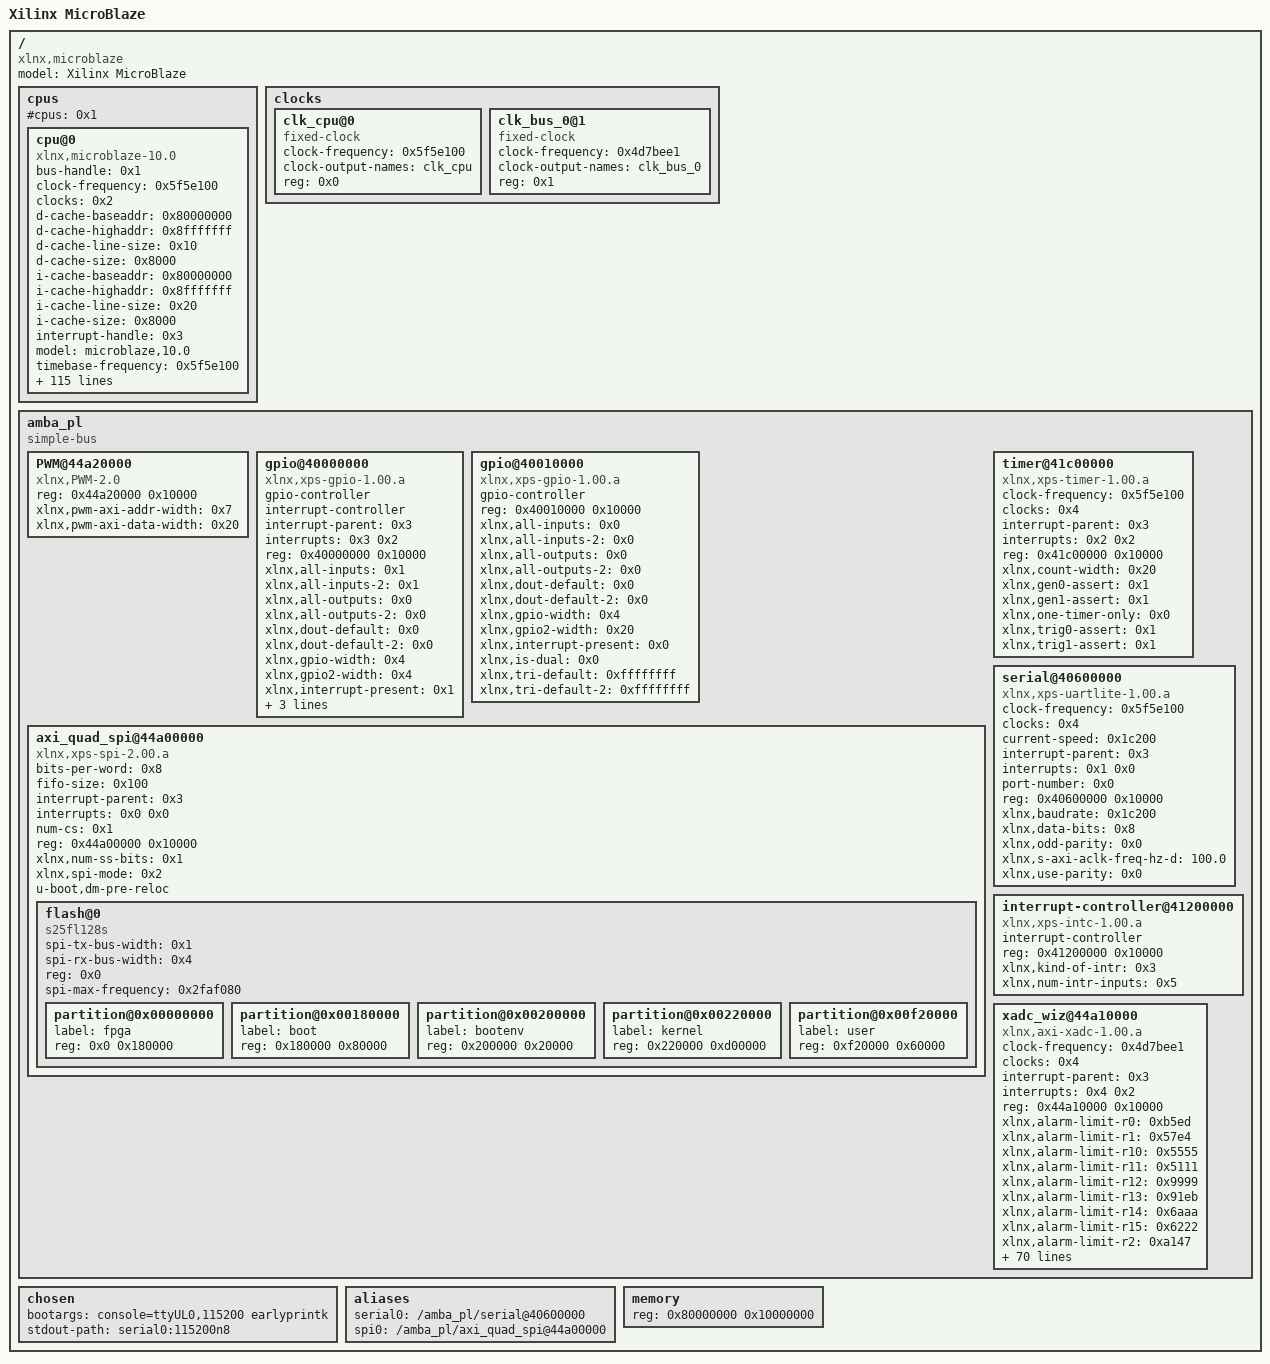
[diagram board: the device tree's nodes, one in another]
/dts-v1/;

/ {
	#address-cells = <0x1>;
	#size-cells = <0x1>;
	compatible = "xlnx,microblaze";
	model = "Xilinx MicroBlaze";

	cpus {
		#address-cells = <0x1>;
		#cpus = <0x1>;
		#size-cells = <0x0>;

		cpu@0 {
			bus-handle = <0x1>;
			clock-frequency = <0x5f5e100>;
			clocks = <0x2>;
			compatible = "xlnx,microblaze-10.0";
			d-cache-baseaddr = <0x80000000>;
			d-cache-highaddr = <0x8fffffff>;
			d-cache-line-size = <0x10>;
			d-cache-size = <0x8000>;
			device_type = "cpu";
			i-cache-baseaddr = <0x80000000>;
			i-cache-highaddr = <0x8fffffff>;
			i-cache-line-size = <0x20>;
			i-cache-size = <0x8000>;
			interrupt-handle = <0x3>;
			model = "microblaze,10.0";
			timebase-frequency = <0x5f5e100>;
			xlnx,addr-size = <0x20>;
			xlnx,addr-tag-bits = <0xd>;
			xlnx,allow-dcache-wr = <0x1>;
			xlnx,allow-icache-wr = <0x1>;
			xlnx,area-optimized = <0x0>;
			xlnx,async-interrupt = <0x1>;
			xlnx,async-wakeup = <0x3>;
			xlnx,avoid-primitives = <0x0>;
			xlnx,base-vectors = <0x0>;
			xlnx,branch-target-cache-size = <0x0>;
			xlnx,cache-byte-size = <0x8000>;
			xlnx,d-axi = <0x1>;
			xlnx,d-lmb = <0x1>;
			xlnx,d-lmb-mon = <0x0>;
			xlnx,daddr-size = <0x20>;
			xlnx,data-size = <0x20>;
			xlnx,dc-axi-mon = <0x0>;
			xlnx,dcache-addr-tag = <0xd>;
			xlnx,dcache-always-used = <0x1>;
			xlnx,dcache-byte-size = <0x8000>;
			xlnx,dcache-data-width = <0x1>;
			xlnx,dcache-force-tag-lutram = <0x0>;
			xlnx,dcache-line-len = <0x4>;
			xlnx,dcache-use-writeback = <0x1>;
			xlnx,dcache-victims = <0x0>;
			xlnx,debug-counter-width = <0x20>;
			xlnx,debug-enabled = <0x1>;
			xlnx,debug-event-counters = <0x5>;
			xlnx,debug-external-trace = <0x0>;
			xlnx,debug-interface = <0x0>;
			xlnx,debug-latency-counters = <0x1>;
			xlnx,debug-profile-size = <0x0>;
			xlnx,debug-trace-async-reset = <0x0>;
			xlnx,debug-trace-size = <0x2000>;
			xlnx,div-zero-exception = <0x1>;
			xlnx,dp-axi-mon = <0x0>;
			xlnx,dynamic-bus-sizing = <0x0>;
			xlnx,ecc-use-ce-exception = <0x0>;
			xlnx,edge-is-positive = <0x1>;
			xlnx,enable-discrete-ports = <0x0>;
			xlnx,endianness = <0x1>;
			xlnx,fault-tolerant = <0x0>;
			xlnx,fpu-exception = <0x1>;
			xlnx,freq = <0x5f5e100>;
			xlnx,fsl-exception = <0x0>;
			xlnx,fsl-links = <0x0>;
			xlnx,i-axi = <0x0>;
			xlnx,i-lmb = <0x1>;
			xlnx,i-lmb-mon = <0x0>;
			xlnx,iaddr-size = <0x20>;
			xlnx,ic-axi-mon = <0x0>;
			xlnx,icache-always-used = <0x1>;
			xlnx,icache-data-width = <0x1>;
			xlnx,icache-force-tag-lutram = <0x0>;
			xlnx,icache-line-len = <0x8>;
			xlnx,icache-streams = <0x1>;
			xlnx,icache-victims = <0x8>;
			xlnx,ill-opcode-exception = <0x1>;
			xlnx,imprecise-exceptions = <0x0>;
			xlnx,instr-size = <0x20>;
			xlnx,interconnect = <0x2>;
			xlnx,interrupt-is-edge = <0x0>;
			xlnx,interrupt-mon = <0x0>;
			xlnx,ip-axi-mon = <0x0>;
			xlnx,lockstep-master = <0x0>;
			xlnx,lockstep-select = <0x0>;
			xlnx,lockstep-slave = <0x0>;
			xlnx,mmu-dtlb-size = <0x4>;
			xlnx,mmu-itlb-size = <0x2>;
			xlnx,mmu-privileged-instr = <0x0>;
			xlnx,mmu-tlb-access = <0x3>;
			xlnx,mmu-zones = <0x2>;
			xlnx,num-sync-ff-clk = <0x2>;
			xlnx,num-sync-ff-clk-debug = <0x2>;
			xlnx,num-sync-ff-clk-irq = <0x1>;
			xlnx,num-sync-ff-dbg-clk = <0x1>;
			xlnx,num-sync-ff-dbg-trace-clk = <0x2>;
			xlnx,number-of-pc-brk = <0x2>;
			xlnx,number-of-rd-addr-brk = <0x1>;
			xlnx,number-of-wr-addr-brk = <0x1>;
			xlnx,opcode-0x0-illegal = <0x1>;
			xlnx,optimization = <0x0>;
			xlnx,pc-width = <0x20>;
			xlnx,piaddr-size = <0x20>;
			xlnx,pvr = <0x2>;
			xlnx,pvr-user1 = <0x0>;
			xlnx,pvr-user2 = <0x0>;
			xlnx,reset-msr = <0x0>;
			xlnx,reset-msr-bip = <0x0>;
			xlnx,reset-msr-dce = <0x0>;
			xlnx,reset-msr-ee = <0x0>;
			xlnx,reset-msr-eip = <0x0>;
			xlnx,reset-msr-ice = <0x0>;
			xlnx,reset-msr-ie = <0x0>;
			xlnx,sco = <0x0>;
			xlnx,trace = <0x0>;
			xlnx,unaligned-exceptions = <0x1>;
			xlnx,use-barrel = <0x1>;
			xlnx,use-branch-target-cache = <0x0>;
			xlnx,use-config-reset = <0x0>;
			xlnx,use-dcache = <0x1>;
			xlnx,use-div = <0x1>;
			xlnx,use-ext-brk = <0x0>;
			xlnx,use-ext-nm-brk = <0x0>;
			xlnx,use-extended-fsl-instr = <0x0>;
			xlnx,use-fpu = <0x1>;
			xlnx,use-hw-mul = <0x2>;
			xlnx,use-icache = <0x1>;
			xlnx,use-interrupt = <0x2>;
			xlnx,use-mmu = <0x3>;
			xlnx,use-msr-instr = <0x1>;
			xlnx,use-non-secure = <0x0>;
			xlnx,use-pcmp-instr = <0x1>;
			xlnx,use-reorder-instr = <0x1>;
			xlnx,use-stack-protection = <0x0>;
		};
	};

	clocks {
		#address-cells = <0x1>;
		#size-cells = <0x0>;

		clk_cpu@0 {
			#clock-cells = <0x0>;
			clock-frequency = <0x5f5e100>;
			clock-output-names = "clk_cpu";
			compatible = "fixed-clock";
			reg = <0x0>;
			linux,phandle = <0x2>;
			phandle = <0x2>;
		};

		clk_bus_0@1 {
			#clock-cells = <0x0>;
			clock-frequency = <0x4d7bee1>;
			clock-output-names = "clk_bus_0";
			compatible = "fixed-clock";
			reg = <0x1>;
			linux,phandle = <0x4>;
			phandle = <0x4>;
		};
	};

	amba_pl {
		#address-cells = <0x1>;
		#size-cells = <0x1>;
		compatible = "simple-bus";
		ranges;
		linux,phandle = <0x1>;
		phandle = <0x1>;

		PWM@44a20000 {
			compatible = "xlnx,PWM-2.0";
			reg = <0x44a20000 0x10000>;
			xlnx,pwm-axi-addr-width = <0x7>;
			xlnx,pwm-axi-data-width = <0x20>;
		};

		gpio@40000000 {
			#gpio-cells = <0x2>;
			#interrupt-cells = <0x2>;
			compatible = "xlnx,xps-gpio-1.00.a";
			gpio-controller;
			interrupt-controller;
			interrupt-parent = <0x3>;
			interrupts = <0x3 0x2>;
			reg = <0x40000000 0x10000>;
			xlnx,all-inputs = <0x1>;
			xlnx,all-inputs-2 = <0x1>;
			xlnx,all-outputs = <0x0>;
			xlnx,all-outputs-2 = <0x0>;
			xlnx,dout-default = <0x0>;
			xlnx,dout-default-2 = <0x0>;
			xlnx,gpio-width = <0x4>;
			xlnx,gpio2-width = <0x4>;
			xlnx,interrupt-present = <0x1>;
			xlnx,is-dual = <0x1>;
			xlnx,tri-default = <0xffffffff>;
			xlnx,tri-default-2 = <0xffffffff>;
		};

		gpio@40010000 {
			#gpio-cells = <0x2>;
			compatible = "xlnx,xps-gpio-1.00.a";
			gpio-controller;
			reg = <0x40010000 0x10000>;
			xlnx,all-inputs = <0x0>;
			xlnx,all-inputs-2 = <0x0>;
			xlnx,all-outputs = <0x0>;
			xlnx,all-outputs-2 = <0x0>;
			xlnx,dout-default = <0x0>;
			xlnx,dout-default-2 = <0x0>;
			xlnx,gpio-width = <0x4>;
			xlnx,gpio2-width = <0x20>;
			xlnx,interrupt-present = <0x0>;
			xlnx,is-dual = <0x0>;
			xlnx,tri-default = <0xffffffff>;
			xlnx,tri-default-2 = <0xffffffff>;
		};

		axi_quad_spi@44a00000 {
			bits-per-word = <0x8>;
			compatible = "xlnx,xps-spi-2.00.a";
			fifo-size = <0x100>;
			interrupt-parent = <0x3>;
			interrupts = <0x0 0x0>;
			num-cs = <0x1>;
			reg = <0x44a00000 0x10000>;
			xlnx,num-ss-bits = <0x1>;
			xlnx,spi-mode = <0x2>;
			u-boot,dm-pre-reloc;
			#address-cells = <0x1>;
			#size-cells = <0x0>;

			flash@0 {
				compatible = "s25fl128s";
				spi-tx-bus-width = <0x1>;
				spi-rx-bus-width = <0x4>;
				reg = <0x0>;
				#address-cells = <0x1>;
				#size-cells = <0x1>;
				spi-max-frequency = <0x2faf080>;

				partition@0x00000000 {
					label = "fpga";
					reg = <0x0 0x180000>;
				};

				partition@0x00180000 {
					label = "boot";
					reg = <0x180000 0x80000>;
				};

				partition@0x00200000 {
					label = "bootenv";
					reg = <0x200000 0x20000>;
				};

				partition@0x00220000 {
					label = "kernel";
					reg = <0x220000 0xd00000>;
				};

				partition@0x00f20000 {
					label = "user";
					reg = <0xf20000 0x60000>;
				};
			};
		};

		timer@41c00000 {
			clock-frequency = <0x5f5e100>;
			clocks = <0x4>;
			compatible = "xlnx,xps-timer-1.00.a";
			interrupt-parent = <0x3>;
			interrupts = <0x2 0x2>;
			reg = <0x41c00000 0x10000>;
			xlnx,count-width = <0x20>;
			xlnx,gen0-assert = <0x1>;
			xlnx,gen1-assert = <0x1>;
			xlnx,one-timer-only = <0x0>;
			xlnx,trig0-assert = <0x1>;
			xlnx,trig1-assert = <0x1>;
		};

		serial@40600000 {
			clock-frequency = <0x5f5e100>;
			clocks = <0x4>;
			compatible = "xlnx,xps-uartlite-1.00.a";
			current-speed = <0x1c200>;
			device_type = "serial";
			interrupt-parent = <0x3>;
			interrupts = <0x1 0x0>;
			port-number = <0x0>;
			reg = <0x40600000 0x10000>;
			xlnx,baudrate = <0x1c200>;
			xlnx,data-bits = <0x8>;
			xlnx,odd-parity = <0x0>;
			xlnx,s-axi-aclk-freq-hz-d = "100.0";
			xlnx,use-parity = <0x0>;
		};

		interrupt-controller@41200000 {
			#interrupt-cells = <0x2>;
			compatible = "xlnx,xps-intc-1.00.a";
			interrupt-controller;
			reg = <0x41200000 0x10000>;
			xlnx,kind-of-intr = <0x3>;
			xlnx,num-intr-inputs = <0x5>;
			linux,phandle = <0x3>;
			phandle = <0x3>;
		};

		xadc_wiz@44a10000 {
			clock-frequency = <0x4d7bee1>;
			clocks = <0x4>;
			compatible = "xlnx,axi-xadc-1.00.a";
			interrupt-parent = <0x3>;
			interrupts = <0x4 0x2>;
			reg = <0x44a10000 0x10000>;
			xlnx,alarm-limit-r0 = <0xb5ed>;
			xlnx,alarm-limit-r1 = <0x57e4>;
			xlnx,alarm-limit-r10 = <0x5555>;
			xlnx,alarm-limit-r11 = <0x5111>;
			xlnx,alarm-limit-r12 = <0x9999>;
			xlnx,alarm-limit-r13 = <0x91eb>;
			xlnx,alarm-limit-r14 = <0x6aaa>;
			xlnx,alarm-limit-r15 = <0x6222>;
			xlnx,alarm-limit-r2 = <0xa147>;
			xlnx,alarm-limit-r3 = <0xca33>;
			xlnx,alarm-limit-r4 = <0xa93a>;
			xlnx,alarm-limit-r5 = <0x52c6>;
			xlnx,alarm-limit-r6 = <0x9555>;
			xlnx,alarm-limit-r7 = <0xae4e>;
			xlnx,alarm-limit-r8 = <0x5999>;
			xlnx,alarm-limit-r9 = <0x5111>;
			xlnx,configuration-r0 = <0x0>;
			xlnx,configuration-r1 = <0x21a0>;
			xlnx,configuration-r2 = <0x1400>;
			xlnx,dclk-frequency = <0x64>;
			xlnx,external-mux = "none";
			xlnx,external-mux-channel = "VP_VN";
			xlnx,external-muxaddr-enable = <0x0>;
			xlnx,fifo-depth = <0x7>;
			xlnx,has-axi = <0x1>;
			xlnx,has-axi4stream = <0x0>;
			xlnx,has-busy = <0x1>;
			xlnx,has-channel = <0x1>;
			xlnx,has-convst = <0x0>;
			xlnx,has-convstclk = <0x0>;
			xlnx,has-dclk = <0x1>;
			xlnx,has-drp = <0x0>;
			xlnx,has-eoc = <0x1>;
			xlnx,has-eos = <0x1>;
			xlnx,has-external-mux = <0x0>;
			xlnx,has-jtagbusy = <0x0>;
			xlnx,has-jtaglocked = <0x0>;
			xlnx,has-jtagmodified = <0x0>;
			xlnx,has-ot-alarm = <0x1>;
			xlnx,has-reset = <0x0>;
			xlnx,has-temp-bus = <0x1>;
			xlnx,has-user-temp-alarm = <0x1>;
			xlnx,has-vbram-alarm = <0x0>;
			xlnx,has-vccaux-alarm = <0x1>;
			xlnx,has-vccddro-alarm = <0x0>;
			xlnx,has-vccint-alarm = <0x1>;
			xlnx,has-vccpaux-alarm = <0x0>;
			xlnx,has-vccpint-alarm = <0x0>;
			xlnx,has-vn = <0x1>;
			xlnx,has-vp = <0x1>;
			xlnx,include-intr = <0x1>;
			xlnx,sampling-rate = "192307.6923076923";
			xlnx,sequence-r0 = <0x900>;
			xlnx,sequence-r1 = <0xf0f>;
			xlnx,sequence-r2 = <0x0>;
			xlnx,sequence-r3 = <0x0>;
			xlnx,sequence-r4 = <0x0>;
			xlnx,sequence-r5 = <0x0>;
			xlnx,sequence-r6 = <0x0>;
			xlnx,sequence-r7 = <0x0>;
			xlnx,sim-file-name = "design";
			xlnx,sim-file-rel-path = "./";
			xlnx,sim-file-sel = "Default";
			xlnx,vaux0 = <0x1>;
			xlnx,vaux1 = <0x1>;
			xlnx,vaux10 = <0x1>;
			xlnx,vaux11 = <0x1>;
			xlnx,vaux12 = <0x0>;
			xlnx,vaux13 = <0x0>;
			xlnx,vaux14 = <0x0>;
			xlnx,vaux15 = <0x0>;
			xlnx,vaux2 = <0x1>;
			xlnx,vaux3 = <0x1>;
			xlnx,vaux4 = <0x0>;
			xlnx,vaux5 = <0x0>;
			xlnx,vaux6 = <0x0>;
			xlnx,vaux7 = <0x0>;
			xlnx,vaux8 = <0x1>;
			xlnx,vaux9 = <0x1>;
		};
	};

	chosen {
		bootargs = "console=ttyUL0,115200 earlyprintk";
		stdout-path = "serial0:115200n8";
	};

	aliases {
		serial0 = "/amba_pl/serial@40600000";
		spi0 = "/amba_pl/axi_quad_spi@44a00000";
	};

	memory {
		device_type = "memory";
		reg = <0x80000000 0x10000000>;
	};
};
